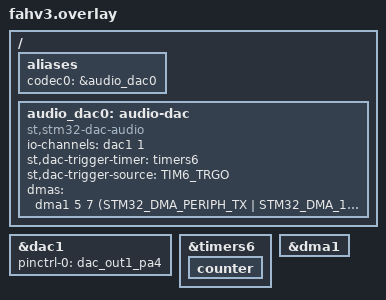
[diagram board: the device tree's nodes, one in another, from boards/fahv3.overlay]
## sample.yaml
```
sample:
  description: onchip audio codec example application
  name: audio codec sample
tests:
  sample.drivers.audio.codec:
    filter: dt_nodelabel_enabled("audcodec")
    tags: codec
    integration_platforms:
      - sf32lb52_devkit_lcd
    harness: console
    harness_config:
      type: multi_line
      ordered: true
      regex:
        - "Audio codec sample"
        - "Exiting"
  sample.drivers.audio.codec.stm32_dac:
    build_only: true
    tags: codec
    platform_allow:
      - nucleo_h743zi
      - nucleo_g474re
      - nucleo_l552ze_q
      - nucleo_f746zg
      - nucleo_f429zi
    integration_platforms:
      - nucleo_h743zi
      - nucleo_g474re
```

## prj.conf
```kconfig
CONFIG_AUDIO=y
#CONFIG_LOG=y
CONFIG_AUDIO_CODEC=y
CONFIG_HEAP_MEM_POOL_SIZE=32000
```

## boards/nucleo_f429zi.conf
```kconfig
CONFIG_AUDIO_CODEC_DAC_STM32=y
```

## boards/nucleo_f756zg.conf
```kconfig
# Feed the DAC by hand from a per-sample timer ISR instead of DMA: same audio,
# ~16000 interrupts/s instead of ~50. Uncomment for the no-DMA trace.
#CONFIG_AUDIO_DAC_STM32_DMA=y
#CONFIG_PM=y

CONFIG_AUDIO_DAC_STM32_TRACE_GPIO=n

CONFIG_TRACING=y
CONFIG_TRACING_CTF=y
CONFIG_TRACING_BACKEND_RAM=y
CONFIG_TRACING_BUFFER_SIZE=2048
CONFIG_RAM_TRACING_BUFFER_SIZE=65536
CONFIG_TRACING_SYNC=y
CONFIG_TRACING_ISR=y
CONFIG_TRACING_SEMAPHORE=y
```

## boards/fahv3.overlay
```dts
/*
 * Copyright (c) 2026 Eve Redero
 *
 * SPDX-License-Identifier: Apache-2.0
 */

/* STM32 DAC audio playback codec on DAC_OUT1 (PA4), streamed on DMA1. */

&dac1 {
	status = "okay";
	pinctrl-0 = <&dac_out1_pa4>;
	pinctrl-names = "default";
};

&timers6 {
	status = "okay";

	counter {
		status = "okay";
	};
};

&dma1 {
	status = "okay";
};

/ {
	aliases {
		codec0 = &audio_dac0;
	};

	audio_dac0: audio-dac {
		compatible = "st,stm32-dac-audio";
		io-channels = <&dac1 1>;
		st,dac-trigger-timer = <&timers6>;
		st,dac-trigger-source = "TIM6_TRGO";
		dmas = <&dma1 5 7
			(STM32_DMA_PERIPH_TX | STM32_DMA_16BITS | STM32_DMA_PRIORITY_HIGH)
			0>;
	};
};
```

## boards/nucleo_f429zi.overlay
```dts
/*
 * Copyright (c) 2026 Eve Redero
 * SPDX-License-Identifier: Apache-2.0
 *
 * STM32F429ZI — DAC1 CH1 audio output
 *   Trigger: TIM6 TRGO
 *   Output:  PA4 (DAC_OUT1)
 *   DMA:     DMA1 Stream 5 Channel 7 (fixed mapping, no DMAMUX)
 */

#include <zephyr/dt-bindings/dma/stm32_dma.h>

/ {
	aliases {
		codec0 = &dac_audio1;
	};
};

&dac_audio1 {
	status = "okay";
	dmas = <&dma1 5 7 (STM32_DMA_PERIPH_TX | STM32_DMA_PRIORITY_HIGH) 0x0>;
	dma-names = "tx";
	pinctrl-0 = <&dac_out1_pa4>;
	pinctrl-names = "default";
};

&timers6 {
	status = "okay";
};

&dma1 {
	status = "okay";
};
```

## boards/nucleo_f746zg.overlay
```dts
/*
 * Copyright (c) 2026 Eve Redero
 * SPDX-License-Identifier: Apache-2.0
 *
 * STM32F746ZG — DAC1 CH1 audio output
 *   Trigger: TIM6 TRGO
 *   Output:  PA4 (DAC_OUT1)
 *   DMA:     DMA1 Stream 5 Channel 7 (fixed mapping, no DMAMUX)
 */

#include <zephyr/dt-bindings/dma/stm32_dma.h>

/ {
	aliases {
		codec0 = &dac_audio1;
	};
};

&dac_audio1 {
	status = "okay";
	dmas = <&dma1 5 7 (STM32_DMA_PERIPH_TX | STM32_DMA_PRIORITY_HIGH) 0x0>;
	dma-names = "tx";
	pinctrl-0 = <&dac_out1_pa4>;
	pinctrl-names = "default";
};

&timers6 {
	status = "okay";
};

&dma1 {
	status = "okay";
};
```

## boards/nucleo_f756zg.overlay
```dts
/*
 * Copyright (c) 2026 Draeger
 *
 * SPDX-License-Identifier: Apache-2.0
 */

&dac1 {
	status = "okay";
	pinctrl-0 = <&dac_out1_pa4>;
	pinctrl-names = "default";
};

&timers6 {
	status = "okay";

	counter {
		status = "okay";
	};
};

&dma1 {
	status = "okay";
};

/ {
	aliases {
		codec0 = &audio_dac0;
	};

	audio_dac0: audio-dac {
		compatible = "st,stm32-dac-audio";
		io-channels = <&dac1 1>;
		st,dac-trigger-timer = <&timers6>;
		st,dac-trigger-source = "TIM6_TRGO";
		dmas = <&dma1 5 7
			(STM32_DMA_PERIPH_TX | STM32_DMA_16BITS | STM32_DMA_PRIORITY_HIGH)
			0>;
	};
};
```

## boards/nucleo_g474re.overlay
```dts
/*
 * Copyright (c) 2026 Eve Redero
 * SPDX-License-Identifier: Apache-2.0
 *
 * STM32G474RE — DAC1 CH1 audio output
 *   Trigger: TIM6 TRGO  (DMAMUX1 slot 6)
 *   Output:  PA4 (DAC_OUT1)
 */

#include <zephyr/dt-bindings/dma/stm32_dma.h>

/ {
	aliases {
		codec0 = &dac_audio1;
	};
};

&dac_audio1 {
	status = "okay";
	dmas = <&dmamux1 0 6 (STM32_DMA_PERIPH_TX | STM32_DMA_PRIORITY_HIGH)>;
	dma-names = "tx";
	pinctrl-0 = <&dac1_out1_pa4>;
	pinctrl-names = "default";
};

&timers6 {
	status = "okay";
};

/* dma1 must be enabled to activate DMA_STM32 Kconfig, which gates DMAMUX_STM32 */
&dma1 {
	status = "okay";
};

&dmamux1 {
	status = "okay";
};
```

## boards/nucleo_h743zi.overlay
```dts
/*
 * Copyright (c) 2026 Eve Redero
 * SPDX-License-Identifier: Apache-2.0
 *
 * STM32H743ZI — DAC1 CH1 audio output
 *   Trigger: TIM6 TRGO  (DMAMUX1 slot 67)
 *   Output:  PA4 (DAC_OUT1)
 */

#include <zephyr/dt-bindings/dma/stm32_dma.h>

/ {
	aliases {
		codec0 = &dac_audio1;
	};
};

&dac_audio1 {
	status = "okay";
	dmas = <&dmamux1 0 67 (STM32_DMA_PERIPH_TX | STM32_DMA_PRIORITY_HIGH)>;
	dma-names = "tx";
	pinctrl-0 = <&dac1_out1_pa4>;
	pinctrl-names = "default";
};

&timers6 {
	status = "okay";
};

/* dma1 must be enabled to activate DMA_STM32 Kconfig, which gates DMAMUX_STM32 */
&dma1 {
	status = "okay";
};

&dmamux1 {
	status = "okay";
};
```

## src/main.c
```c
/*
 * Copyright 2025 SiFli Technologies(Nanjing) Co., Ltd
 *
 * SPDX-License-Identifier: Apache-2.0
 */

#include <stdio.h>
#include <zephyr/device.h>
#include <zephyr/kernel.h>
#include <zephyr/devicetree.h>
#include <zephyr/audio/codec.h>
#include <zephyr/logging/log.h>
#include "sine.h"
#include <zephyr/tracing/tracing.h>
LOG_MODULE_REGISTER(codec_sample);

#define AUDIO_BLOCK_SIZE 218
#define SPEAKER_VOL      15

static bool loopback;
static uint8_t *audio_data_p;

/* The playback loop only emits whole AUDIO_BLOCK_SIZE chunks, so the buffer must
 * be an exact multiple of the block or its tail would never be played.
 */
BUILD_ASSERT(sizeof(wave_table) % AUDIO_BLOCK_SIZE == 0,
	     "PCM buffer must be a whole number of AUDIO_BLOCK_SIZE blocks");

static void tx_done(const struct device *dev, void *user_data)
{
	if (!loopback) {
		size_t offset = (size_t)(audio_data_p - wave_table);
		size_t remaining = sizeof(wave_table) - offset;

		if (remaining < AUDIO_BLOCK_SIZE) {
			audio_data_p = wave_table;
		}
		sys_trace_named_event("refill", 0, 0);
		audio_codec_write(dev, audio_data_p, AUDIO_BLOCK_SIZE);
		audio_data_p += AUDIO_BLOCK_SIZE;
	}
}
static void rx_done(const struct device *dev, uint8_t *buf, uint32_t len, void *user_data)
{
	if (loopback) {
		audio_codec_write(dev, buf, AUDIO_BLOCK_SIZE);
	}
}

int main(void)
{
	static const struct device *dev;
	audio_property_value_t val;
	struct audio_codec_cfg cfg = {
		.dai_type = AUDIO_DAI_TYPE_PCM,
		.dai_cfg.pcm.dir = AUDIO_DAI_DIR_TX,
		.dai_cfg.pcm.pcm_width = AUDIO_PCM_WIDTH_16_BITS,
		.dai_cfg.pcm.channels = 1,
		.dai_cfg.pcm.block_size = AUDIO_BLOCK_SIZE,
		.dai_cfg.pcm.samplerate = AUDIO_PCM_RATE_48K,
	};

	LOG_INF("Audio codec sample");
#if DT_NODE_HAS_STATUS_OKAY(DT_ALIAS(codec0))
	dev = DEVICE_DT_GET(DT_ALIAS(codec0));
#else
	LOG_ERR("No audio codec on this board. Skipping audio test.\n");
	return 0;
#endif
	if (!device_is_ready(dev)) {
		LOG_ERR("codec device is not ready\n");
		return -EBUSY;
	}
	LOG_INF("codec device is ready");
	k_sleep(K_MSEC(1000));

	LOG_INF("codec playback example");
	loopback = false;
	audio_data_p = wave_table;
	if (audio_codec_configure(dev, &cfg) < 0) {
		LOG_ERR("configure codec error\n");
		return -EIO;
	}
	if (audio_codec_register_done_callback(dev, tx_done, NULL, rx_done, NULL) < 0) {
		LOG_ERR("could not register codec callbacks\n");
		return -EIO;
	}
	audio_codec_start(dev, AUDIO_DAI_DIR_TX);
	LOG_INF("playback started");
	val.vol = SPEAKER_VOL;
	if (audio_codec_set_property(dev, AUDIO_PROPERTY_OUTPUT_VOLUME, 0, val) < 0) {
		LOG_ERR("could not set volume\n");
		return -EIO;
	}
	k_sleep(K_MSEC(6000));
#if 1
	int i = 0;
	for (i=0; i < 0xFFFF; i++) {
		printk(".");
	}
#endif

	audio_codec_stop(dev, AUDIO_DAI_DIR_TX);
	LOG_INF("codec transfer stopped");

	LOG_INF("Exiting");
	return 0;
}
```

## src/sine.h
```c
// Generating 440 Hz sine wave at 48000 Hz sample rate
// Samples per period: 109
// Actual frequency: 440.37 Hz

/*
 * SPDX-License-Identifier: Apache-2.0
 *
 * 440 Hz sine wave sampled at 48 kHz
 * 109 samples per period, 218 bytes total
 */

#ifndef SINE_H_
#define SINE_H_

/* PCM data is word-aligned for efficient access (e.g. by the codec/DMA).
 */
static uint8_t __aligned(4) wave_table[] = {
	0xFF, 0x07, 0x74, 0x08, 0xEA, 0x08, 0x5F, 0x09, 0xD2, 0x09, 0x44, 0x0A, 0xB4, 0x0A, 0x22,
	0x0B, 0x8D, 0x0B, 0xF5, 0x0B, 0x5A, 0x0C, 0xBB, 0x0C, 0x18, 0x0D, 0x71, 0x0D, 0xC5, 0x0D,
	0x14, 0x0E, 0x5E, 0x0E, 0xA2, 0x0E, 0xE1, 0x0E, 0x1A, 0x0F, 0x4D, 0x0F, 0x7A, 0x0F, 0xA0,
	0x0F, 0xC0, 0x0F, 0xDA, 0x0F, 0xEC, 0x0F, 0xF8, 0x0F, 0xFD, 0x0F, 0xFC, 0x0F, 0xF3, 0x0F,
	0xE4, 0x0F, 0xCE, 0x0F, 0xB1, 0x0F, 0x8E, 0x0F, 0x64, 0x0F, 0x35, 0x0F, 0xFF, 0x0E, 0xC3,
	0x0E, 0x81, 0x0E, 0x3A, 0x0E, 0xED, 0x0D, 0x9B, 0x0D, 0x45, 0x0D, 0xEA, 0x0C, 0x8B, 0x0C,
	0x28, 0x0C, 0xC2, 0x0B, 0x58, 0x0B, 0xEC, 0x0A, 0x7D, 0x0A, 0x0C, 0x0A, 0x99, 0x09, 0x24,
	0x09, 0xAF, 0x08, 0x39, 0x08, 0xC4, 0x07, 0x4E, 0x07, 0xD9, 0x06, 0x64, 0x06, 0xF1, 0x05,
	0x80, 0x05, 0x11, 0x05, 0xA5, 0x04, 0x3B, 0x04, 0xD5, 0x03, 0x72, 0x03, 0x13, 0x03, 0xB8,
	0x02, 0x62, 0x02, 0x10, 0x02, 0xC3, 0x01, 0x7C, 0x01, 0x3A, 0x01, 0xFE, 0x00, 0xC8, 0x00,
	0x99, 0x00, 0x6F, 0x00, 0x4C, 0x00, 0x2F, 0x00, 0x19, 0x00, 0x0A, 0x00, 0x01, 0x00, 0x00,
	0x00, 0x05, 0x00, 0x11, 0x00, 0x23, 0x00, 0x3D, 0x00, 0x5D, 0x00, 0x83, 0x00, 0xB0, 0x00,
	0xE3, 0x00, 0x1C, 0x01, 0x5B, 0x01, 0x9F, 0x01, 0xE9, 0x01, 0x38, 0x02, 0x8C, 0x02, 0xE5,
	0x02, 0x42, 0x03, 0xA3, 0x03, 0x08, 0x04, 0x70, 0x04, 0xDB, 0x04, 0x49, 0x05, 0xB9, 0x05,
	0x2B, 0x06, 0x9E, 0x06, 0x13, 0x07, 0x89, 0x07
};

#endif /* SINE_H_ */
```
